# ATmega16U4 device description
Architecture: AVR8; Family: megaAVR
Registers are 8-bit, access not given, no defined reset value unless marked. A register's access mark holds for its fields unless they carry their own. Offsets are from the block's base; [hi:lo] are bit positions; {n}, {i} and the like mark numbered series; 'fields as' and 'values as' point back to an identical list.

## JTAG — JTAG Interface
Instances: JTAG 0x00
0x51 OCDR — On-Chip Debug Related Register in I/O Memory
0x54 MCUSR — MCU Status Register
  [4] JTRF — JTAG Reset Flag
0x55 MCUCR — MCU Control Register
  [7] JTD — JTAG Interface Disable

## EXINT — External Interrupts
Instances: EXINT 0x00
0x3B PCIFR — Pin Change Interrupt Flag Register
  [0] PCIF0 — Pin Change Interrupt Flag 0
0x3C EIFR — External Interrupt Flag Register
  [7:0] INTF — External Interrupt Flags
0x3D EIMSK — External Interrupt Mask Register
  [7:0] INT — External Interrupt Request 7 Enable
0x68 PCICR — Pin Change Interrupt Control Register
  [0] PCIE0 — Pin Change Interrupt Enable 0
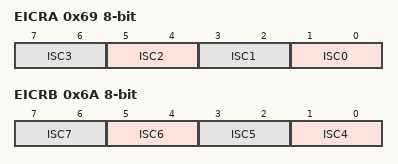
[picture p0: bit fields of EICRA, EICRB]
0x69 EICRA — External Interrupt Control Register A
  [all] fields
    0=Low Level of INTX; 1=Any Logical Change of INTX; 2=Falling Edge of INTX; 3=Rising Edge of INTX
  [2n+1:2n] ISC{n} (n=0..3) — External Interrupt Sense Control Bit
0x6A EICRB — External Interrupt Control Register B
  [all] fields
    values as the fields of EICRA
  [2n-7:2n-8] ISC{n} (n=4..7) — External Interrupt 7-4 Sense Control Bit
0x6B PCMSK0 — Pin Change Mask Register 0
  [7:0] PCINT — Pin Change Mask 0

## TWI — Two Wire Serial Interface
Instances: TWI 0x00
0xB8 TWBR — TWI Bit Rate register
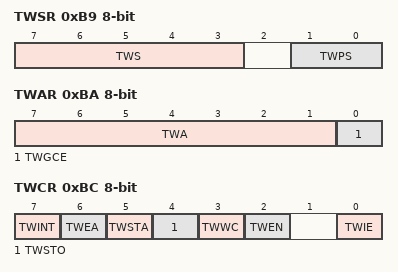
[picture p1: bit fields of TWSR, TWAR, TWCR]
0xB9 TWSR — TWI Status Register
  [7:3] TWS (bit 3 of the value upward) — TWI Status
  [1:0] TWPS — TWI Prescaler
    0=1; 1=4; 2=16; 3=64
0xBA TWAR — TWI (Slave) Address register
  [7:1] TWA — TWI (Slave) Address register Bits
  [0] TWGCE — TWI General Call Recognition Enable Bit
0xBB TWDR — TWI Data register
0xBC TWCR — TWI Control Register
  [7] TWINT — TWI Interrupt Flag
  [6] TWEA — TWI Enable Acknowledge Bit
  [5] TWSTA — TWI Start Condition Bit
  [4] TWSTO — TWI Stop Condition Bit
  [3] TWWC — TWI Write Collition Flag
  [2] TWEN — TWI Enable Bit
  [0] TWIE — TWI Interrupt Enable
0xBD TWAMR — TWI (Slave) Address Mask Register
  [7:1] TWAM

## ADC — Analog-to-Digital Converter
Instances: ADC 0x00
0x78 ADC 16-bit — ADC Data Register Bytes
  [9:0] ADC — ADC Data Bits
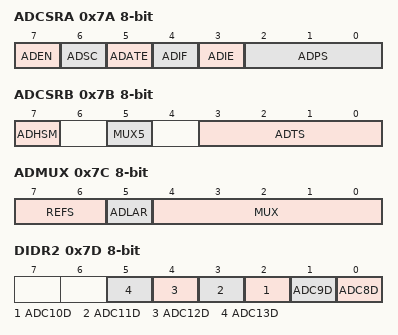
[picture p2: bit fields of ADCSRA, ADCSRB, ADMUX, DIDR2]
0x7A ADCSRA — The ADC Control and Status register
  [7] ADEN — ADC Enable
  [6] ADSC — ADC Start Conversion
  [5] ADATE — ADC Auto Trigger Enable
  [4] ADIF — ADC Interrupt Flag
  [3] ADIE — ADC Interrupt Enable
  [2:0] ADPS — ADC Prescaler Select Bits
    0=2; 1=2; 2=4; 3=8; 4=16; 5=32; 6=64; 7=128
0x7B ADCSRB — ADC Control and Status Register B
  [7] ADHSM — ADC High Speed Mode
  [5] MUX5 — Analog Channel and Gain Selection Bits
  [3:0] ADTS — ADC Auto Trigger Sources
    0=Free Running mode; 1=Analog Comparator; 2=External Interrupt Request 0; 3=Timer/Counter0 Compare Match A; 4=Timer/Counter0 Overflow; 5=Timer/Counter1 Compare Match B; 6=Timer/Counter1 Overflow; 7=Timer/Counter1 Capture Event
0x7C ADMUX — The ADC multiplexer Selection Register
  [7:6] REFS — Reference Selection Bits
    0=AREF, Internal Vref turned off; 1=AVCC with external capacitor at AREF pin; 3=Internal 2.56V Voltage Reference with external capacitor at AREF pin
  [5] ADLAR — Left Adjust Result
  [4:0] MUX — Analog Channel and Gain Selection Bits
0x7D DIDR2 — Digital Input Disable Register 1
  [n-8] ADC{n}D (n=8..13) — ADC{n} Digital input Disable
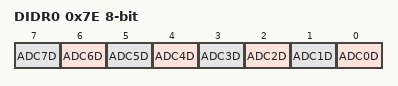
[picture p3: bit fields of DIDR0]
0x7E DIDR0 — Digital Input Disable Register 1
  [n] ADC{n}D (n=0..7) — ADC{n} Digital input Disable

## AC — Analog Comparator
Instances: AC 0x00
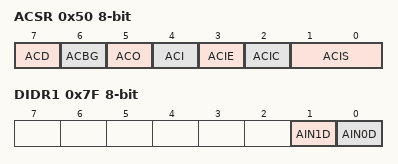
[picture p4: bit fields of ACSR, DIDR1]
0x50 ACSR — Analog Comparator Control And Status Register
  [7] ACD — Analog Comparator Disable
  [6] ACBG — Analog Comparator Bandgap Select
  [5] ACO — Analog Compare Output
  [4] ACI — Analog Comparator Interrupt Flag
  [3] ACIE — Analog Comparator Interrupt Enable
  [2] ACIC — Analog Comparator Input Capture Enable
  [1:0] ACIS — Analog Comparator Interrupt Mode Select bits
    0=Interrupt on Toggle; 2=Interrupt on Falling Edge; 3=Interrupt on Rising Edge
0x7B ADCSRB — ADC Control and Status Register B
  [6] ACME — Analog Comparator Multiplexer Enable
0x7F DIDR1
  [1] AIN1D — AIN1 Digital Input Disable
  [0] AIN0D — AIN0 Digital Input Disable
